# moonlight_application register map
Vendor: Nordic Semiconductor; Series: lumos; File version: 1
CPU: CM33 r0p4, little endian, MPU, FPU, 3 interrupt priority bits, 176 interrupts, 4 SAU regions
Registers are 32-bit, read-write, reset 0x0 unless marked. A register's access mark holds for its fields unless they carry their own. Offsets are from the block's base; [hi:lo] are bit positions; lines under a group give offsets from that group; {n}, {i} and the like mark numbered series; 'fields as' and 'values as' point back to an identical list.

## GLOBAL_REGULATORS_NS — Voltage regulators 0
Base 0x40120000; alternate view of GLOBAL_OSCILLATORS_NS
Same registers: GLOBAL_REGULATORS_S 0x50120000 (alternate view of GLOBAL_OSCILLATORS_S)
0x400 VREGM group — Medium Voltage Regulator
  0x00 ENABLE reset 0x1 — Unspecified
    [0] ENABLE — Enable the regulator
      0=Disabled (Disable the regulator); 1=Enabled (Enable the regulator)
  0x10 VOLT — Set output voltage
    [2:0] VOLT
      0=2V6 (2.6 V); 1=2V7 (2.7 V); 2=2V8 (2.8 V); 3=2V9 (2.9 V); 4=3V0 (3.0 V); 5=3V1 (3.1 V); 6=3V2 (3.2 V); 7=3V3 (3.3 V)
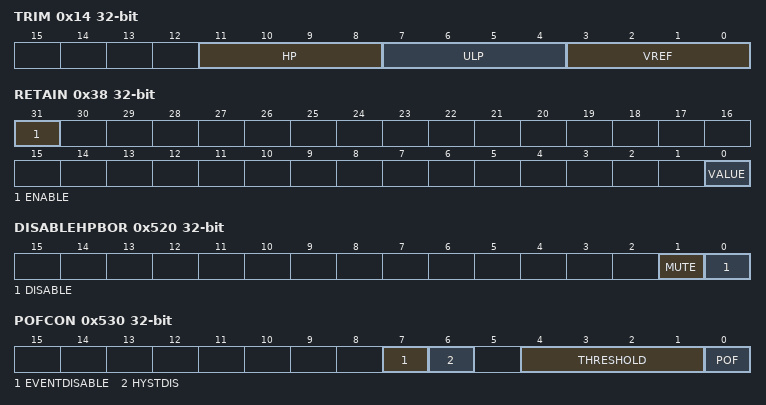
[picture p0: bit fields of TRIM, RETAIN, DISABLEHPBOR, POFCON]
  0x14 TRIM — Unspecified
    [11:8] HP — VOUT
    [7:4] ULP — VOUTCOMP TH ie Refresh Ripple
    [3:0] VREF — VFREF_MBIAS
  0x30 READY ro — Unspecified
    [0] READY — Regulator ready
  0x34 BPREADY ro — Unspecified
    [0] BPREADY — Bypass mode flag
  0x38 RETAIN — Override the retention control signal to the regulator for testing.
    [31] ENABLE — Override enable
    [0] VALUE — Override value
  0x3C DTBCFG — Unspecified
    [2:0] DTB0CFG — Using 3 bits of DTB0CFG allows to hook four internal signals to DTB. VOUTCMP is needed for test but others are free choice for debug.
      4=VOUTCOMP (Unspecified); 5=PWRUPFB (Unspecified); 6=PWRUPVREG (Unspecified); 7=BYPASS (Unspecified)
  0x40 TCFG — Unspecified
    [7:0] TCFG — TCFG test force configuration bus.
      0=PWRUPVOUTCMP (Unspecified); 2=PWRUPFB (Unspecified); 4=PWRUPVREG (Unspecified); 8=BYPASS (Unspecified); 16=FORCEULP (Unspecified); 32=FORCEBP (Unspecified); 64=DISABLEMBIAS (Unspecified); 128=RESETDIG (Unspecified)
0x500 SYSTEMOFF wo
  [0] SYSTEMOFF — Enable System OFF mode
    1=Enter (Enable System OFF mode)
0x520 DISABLEHPBOR wo — Enable or disable HPBOR
  [1] MUTE — Mute or unmute HPBOR
    0=Unmuted (Unmute HPBOR); 1=Muted (Mute HPBOR)
  [0] DISABLE — Enable or disable HPBOR
    0=Enabled (Enable HPBOR); 1=Disabled (Disable HPBOR)
0x524 BIASREQUEST — Request BIAS module
  [0] REQ
    0=Automatic (Bias is requested automatically by users); 1=Requested (Bias is always requested)
0x530 POFCON — Power-fail comparator configuration
  [7] EVENTDISABLE — Disable the POFWARN power-fail warning event
    0=Enabled (POFWARN event is generated); 1=Disabled (POFWARN event is not generated)
  [6] HYSTDIS — Bypass power-fail comparator hysteresis
    0=Normal (Hysteresis active); 1=NoHyst (Hysteresis disabled)
  [4:1] THRESHOLD — Power-fail comparator threshold setting
    4=V17 (Set threshold to 1.7 V); 5=V18 (Set threshold to 1.8 V); 6=V19 (Set threshold to 1.9 V); 7=V20 (Set threshold to 2.0 V); 8=V21 (Set threshold to 2.1 V); 9=V22 (Set threshold to 2.2 V); 10=V23 (Set threshold to 2.3 V); 11=V24 (Set threshold to 2.4 V); 12=V25 (Set threshold to 2.5 V); 13=V26 (Set threshold to 2.6 V); 14=V27 (Set threshold to 2.7 V); 15=V28 (Set threshold to 2.8 V)
  [0] POF — Enable or disable power-fail comparator
    0=Disabled; 1=Enabled
0x534 POFSTAT ro — Power-fail comparator status register
  [0] COMPARATOR — Power-fail comparator status
    0=Above (Voltage detected above VPOF threshold); 1=Below (Voltage detected below VPOF threshold)
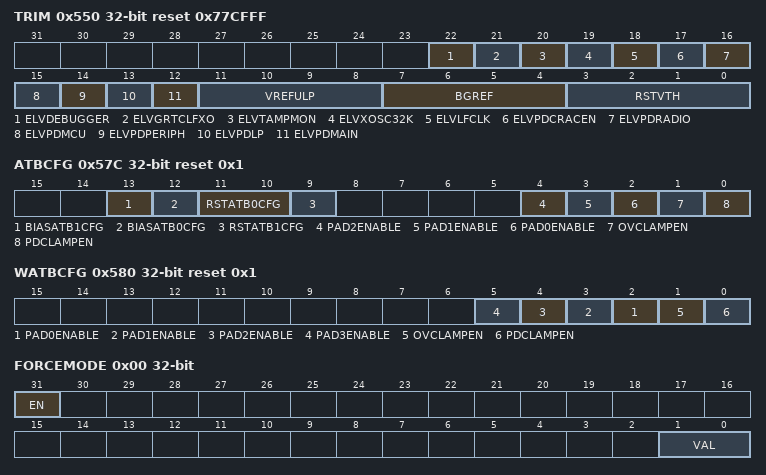
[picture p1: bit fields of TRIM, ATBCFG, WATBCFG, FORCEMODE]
0x550 TRIM reset 0x77CFFF — TRIM values
  [22] ELVDEBUGGER — Allow or prevent ELV mode when DEBUGGER is connected
    0=Allow ELV mode when DEBUGGER is connected; 1=Prevent ELV mode when DEBUGGER is connected
  [21] ELVGRTCLFXO — Allow or prevent ELV mode when GRTC is ON in LFXO source
    0=Allow ELV mode when GRTC is ON in LFXO source; 1=Prevent ELV mode when GRTC is ON in LFXO source
  [20] ELVTAMPMON — Allow or prevent ELV mode when TAMPMON is ON
    0=Allow ELV mode when TAMPMON is ON; 1=Prevent ELV mode when TAMPMON is ON
  [19] ELVXOSC32K — Allow or prevent ELV mode when XOSC32K is ON
    0=Allow ELV mode when XOSC32K is ON; 1=Prevent ELV mode when XOSC32K is ON
  [18] ELVLFCLK — Allow or prevent ELV mode when LFCLK is ON
    0=Allow ELV mode when LFCLK is ON; 1=Prevent ELV mode when LFCLK is ON
  [17] ELVPDCRACEN — Allow or prevent ELV mode when PD_CRACEN is ON
    0=Allow ELV mode when PD_CRACEN is ON; 1=Prevent ELV mode when PD_CRACEN is ON
  [16] ELVPDRADIO — Allow or prevent ELV mode when PD_RADIO is ON
    0=Allow ELV mode when PD_RADIO is ON; 1=Prevent ELV mode when PD_RADIO is ON
  [15] ELVPDMCU — Allow or prevent ELV mode when PD_PERIPH is ON
    0=Allow ELV mode when PD_PERIPH is ON; 1=Prevent ELV mode when PD_PERIPH is ON
  [14] ELVPDPERIPH — Allow or prevent ELV mode when PD_PERIPH is ON
    values as ELVPDMCU
  [13] ELVPDLP — Allow or prevent ELV mode when PD_LP is ON
    0=Allow ELV mode when PD_LP is ON; 1=Prevent ELV mode when PD_LP is ON
  [12] ELVPDMAIN — Allow or prevent ELV mode when PD_MAIN is ON
    0=Allow ELV mode when PD_MAIN is ON; 1=Prevent ELV mode when PD_MAIN is ON
  [11:8] VREFULP — Trim value of VREF_ULP
  [7:4] BGREF — Master bias bandgap trim
  [3:0] RSTVTH — Threshold trim, power-on reset
0x57C ATBCFG reset 0x1 — Analog test bus control
  [13] BIASATB1CFG — Connect or disconnect MBIAS to analog test bus
    0=Disconnect from analog test bus; 1=Connect IBPSR_8U current to ATB1
  [12] BIASATB0CFG — Connect or disconnect MBIAS to analog test bus
    0=Disconnect from analog test bus; 1=Connect VBG voltage to ATB0
  [11:10] RSTATB0CFG — Configure connection of RST to analog test bus
    0=Disconnect from analog test bus; 1=AVDD_DIV2 connected to ATB0; 2=VREF_ULP connected to ATB0; 3=VBG_RST connected to ATB0
  [9] RSTATB1CFG — Configure connection of RST to analog test bus
    0=Disconnect from analog test bus; 1=Connect (IBPP connected to ATB1)
  [4] PAD2ENABLE — Enable or disable ATB2 pad
    0=Disabled (Disable pad); 1=Enable pad
  [3] PAD1ENABLE — Enable or disable ATB1 pad
    0=Disabled (Disable pad); 1=Enable pad
  [2] PAD0ENABLE — Enable or disable ATB0 pad
    0=Disabled (Disable pad); 1=Enable pad
  [1] OVCLAMPEN — Enable or disable overvoltage clamp on ATB
    0=Disabled (Disable overvoltage clamp); 1=Enable overvoltage clamp
  [0] PDCLAMPEN — Enable or disable power-down clamp on ATB
    0=Disable power-down clamp; 1=Enable power-down clamp
0x580 WATBCFG reset 0x1 — WATB control
  [n+2] PAD{n}ENABLE (n=0..3) — Enable or disable WATB{n} pad
    0=Disabled (Disable pad); 1=Enable pad
  [1] OVCLAMPEN — Enable or disable overvoltage clamp on WATB
    values as ATBCFG.OVCLAMPEN
  [0] PDCLAMPEN — Enable or disable power-down clamp on WATB
    0=Disable power-down clamp; 1=Enable power-down clamp
0x600 VREGMAIN group — Main voltage regulator
  0x00 DCDCEN — Enable DC/DC converter for better power efficiency
    [0] VAL — Enable DC/DC converter
      0=Disable DC/DC converter and use LDO; 1=Enable DC/DC converter
  0x04 INDUCTORDET ro — VREGMAIN inductor detection
    [0] DETECTED
      0=InductorNotDetected (VREGMAIN inductor not detected); 1=InductorDetected (VREGMAIN inductor detected)
  0x08 STATUS ro — Voltage regulator status
    [5:0] MODE — Current voltage regulator mode
      8=Ext (External supply mode); 9=Ldo (Linear low drop output mode - a high power, low efficiency mode); 10=Pfm (Pulse frequency modulation mode - a low power, high efficiency mode); 12=Pwm (Pulse width modulation mode - a high power, high efficiency, and clean power (low noise) mode); 1=Reset mode; 41=ExtLdo (Transition state between EXT to LDO); 11=PfmLdo (Transition state between PFM to LDO); 13=LdoPwm (Transition state between LDO and PWM); 14=PfmPwm (Transition state between PFM to PWM); 46=PwmPfm (Transition state between PWM to PFM); 28=PwmIcmp (Transition state between PWM to PWM_PFM, where the FSM waits for the PWM ICMP)
  0x0C PFMICMPRUNNING ro — Current PFM ICMP status
    [0] TIMERRUNNING
      0=NotRunning (PFM ICMP timer is not running); 1=Running (PFM ICMP timer is running)
  0x10 PFMICMPFLAG — PFM ICMP has been triggered (write one to clear it)
    [0] PFMICMPFLAG
      0=NotTriggered (PFM ICMP has not been triggered); 1=Triggered (PFM ICMP has been triggered)
  0x14 BUCKLSCOUNT ro — Read counter output controlling low-side current threshold for PFM mode
    [4:0] BUCKLSCOUNT
  0x18 CONFIG group — Configure the MMI behavior
    0x00 FORCEMODE — Force voltage regulator into a certain mode
      [31] EN — Enable force mode for the regulator
        0=Disabled (Force mode is disabled); 1=Enabled (Force mode is enabled)
      [1:0] VAL — Current voltage regulator mode
        0=Ext (Force to external supply mode); 1=Ldo (Force to LDO mode); 2=Pfm (Force to PFM mode); 3=Pwm (Force to PWM mode)
    0x04 DEBUGCONTROL — Analog module debug control signals
      [7:0] VAL
        0=Bit0 (Enable resistive feedback for DC/DC converter (PFM mode)); 1=Bit1 (Turn off P_DCC_LP (PWM mode)); 2=Bit2 (Prevent comparator from turning off high side driver (PFM mode)); 3=Bit3 (Force BUCK_ICMP_0V9 to 0 (PFM mode)); 4=Bit4 (Force low side driver on); 5=Bit5 (Force high side driver on)
    0x08 VREGENLOAD — Enable test load for P_LR0V9 pad
      [0] VAL
        0=NormalOperation (No load); 1=TestLoad (88 Ohm test load, about 10mA load current at 0.9V)
    0x0C BUCKSETLSCOUNTER — Force the counter in the zero-cross detector to the set value for PFM mode
      [5:0] BUCKSETLSCOUNTER
    0x10 REQUESTEXTERNAL — Request external mode, and switch OFF the regulator
      [0] VAL — Request external mode for the regulator
        0=Disabled (External mode is not requested); 1=Enabled (External mode is requested)
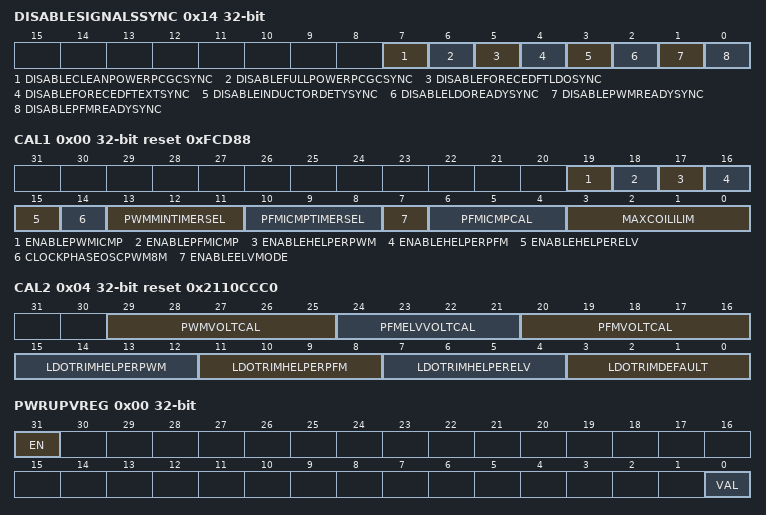
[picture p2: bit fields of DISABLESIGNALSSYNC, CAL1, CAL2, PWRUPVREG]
    0x14 DISABLESIGNALSSYNC — Disable Signals synchronization
      [all] fields
        0=Enable (Synchronization is enabled); 1=Disable (Synchronization is disabled)
      [7] DISABLECLEANPOWERPCGCSYNC — Disable cleanPowerPcgc signal synchronization
      [6] DISABLEFULLPOWERPCGCSYNC — Disable fullPowerPcgc signal synchronization
      [5] DISABLEFORECEDFTLDOSYNC — Disable forceDftLdo signal synchronization
      [4] DISABLEFORECEDFTEXTSYNC — Disable forceDftExt signal synchronization
      [3] DISABLEINDUCTORDETYSYNC — Disable inductorDetect signal synchronization
      [2] DISABLELDOREADYSYNC — Disable ldoReady signal synchronization
      [1] DISABLEPWMREADYSYNC — Disable pwmReady signal synchronization
      [0] DISABLEPFMREADYSYNC — Disable pfmReady signal synchronization
    0x18 ATB0CFG — Analog testbus 0 configuration
      [3:0] ATB0CFG
        0=HiZ (Allow other IPs to use ATB0); 1=InvertedBuckComparator (Inverting input of buck comparator); 2=InvertedBuckErrorAmplifier (Inverting input of buck error amplifier); 3=BuckInternalRegerence (Buck Internal bandgap reference); 4=VDD analog voltage; 5=VDD digital voltage
    0x1C ATB1CFG — Analog testbus 1 configuration
      [3:0] ATB1CFG
        0=HiZ (Allow other IPs to use ATB1); 1=BuckComparator (Non-inverting input of buck comparator); 2=BuckErrorAmplifier (Output of buck error amplifier); {v}=VSS{v-3} (VSS analog voltage) (v=4..7)
    0x20 DTB0CFG — Digital testbus 0 configuration
      [2:0] DTB0CFG
        0=Dtb0Low (Allow other IPs to use DTB0); 1=BuckLsIlim (TODO: Update abstract); 2=CmpBuf (TODO: Update abstract); 3=AfsmS0 (TODO: Update abstract)
    0x24 DTB1CFG — Digital testbus 1 configuration
      [2:0] DTB1CFG
        0=Dtb1Low (Allow other IPs to use DTB1); 1=BuckHsIlim (TODO: Update abstract); 2=BuckPfmIcmp (TODO: Update abstract); 3=AfsmS1 (TODO: Update abstract)
  0x40 CALIBRATION group — Calibration values written from FICR
    0x00 CAL1 reset 0xFCD88 — Unspecified
      [19] ENABLEPWMICMP — Enable PWM ICMP (to auto detect no high load current is present)
      [18] ENABLEPFMICMP — Enable PFM ICMP (to auto detect high load)
      [17] ENABLEHELPERPWM — Enable helper mode in PWM mode (LDO will be powered ON)
      [16] ENABLEHELPERPFM — Enable helper mode in PFM mode (LDO will be powered ON)
      [15] ENABLEHELPERELV — Enable fast exit from ELV (helper mode in ELV, LDO will be powered ON)
      [14] CLOCKPHASEOSCPWM8M — Configure the generated DCDC clock phase (for PWM mode) with respect to the orignal system clock, 0 in phase and 1 is out of phase
      [13:11] PWMMINTIMERSEL — Configure the minimum time to stay in PWM mode after a PWM mode request. The timer has a minimum value of 32us and maximum value of 256us (value = ((32*(n + 1) - 1))us), with linear increments of 32us (32us, 64us, 96us, etc..) with 3 bits to select the timer value
      [10:8] PFMICMPTIMERSEL — Configure the time to stay in PWM mode after a PFM ICMP request. The timer has a minimum value of 32us and maximum value of 4ms (value = ((32*(2^n) - 1))us), with exponential increments (32us, 64us, 128us, etc..) with 3 bits to select the timer value
      [7] ENABLEELVMODE — Enable ELV mode (Extreme Low Voltage) to be automatically switched to in PFM mode if there is no power requests
      [6:4] PFMICMPCAL — Calibration of PFM mode overcurrent comparator through duty cycle control (2's complement)
      [3:0] MAXCOILILIM — Set coil current limit to avoid core saturation
    0x04 CAL2 reset 0x2110CCC0 — Unspecified
      [29:25] PWMVOLTCAL — Calibration of BUCK_LP_PWM output voltage
      [24:21] PFMELVVOLTCAL — Calibration of ELV output voltage
      [20:16] PFMVOLTCAL — Calibration of BUCK_LP_PFM output voltage
      [15:12] LDOTRIMHELPERPWM — Calibration of LDO reference voltage for PWM helper mode operation, 2nd complement
      [11:8] LDOTRIMHELPERPFM — Calibration of LDO reference voltage for PFM helper mode operation, 2nd complement
      [7:4] LDOTRIMHELPERELV — Calibration of LDO reference voltage for ELV helper mode operation, 2nd complement
      [3:0] LDOTRIMDEFAULT — Calibration of LDO reference voltage for normal operation, 2nd complement
  0x48 OVERRIDE group — Override analog IP signals
    0x00 PWRUPVREG — Override the PWRUP signal for LDO (Vreg) to the analog module
      [31] EN — Enable the override
        0=Disabled (Override is disabled); 1=Enabled (Override is enabled)
      [0] VAL — Override value
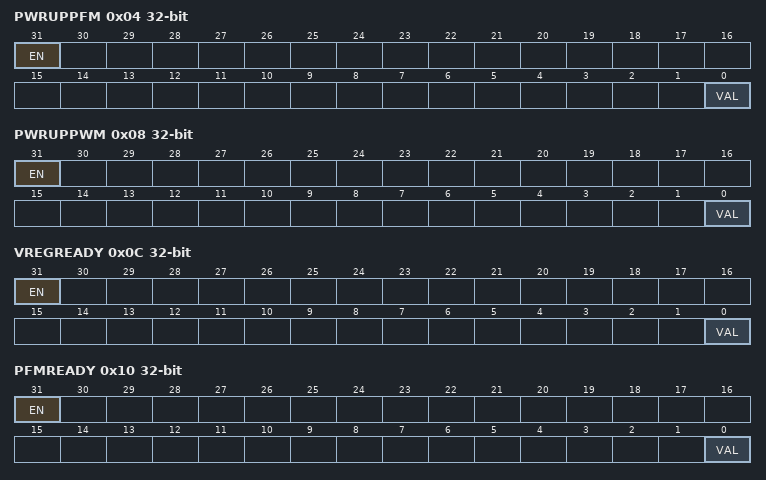
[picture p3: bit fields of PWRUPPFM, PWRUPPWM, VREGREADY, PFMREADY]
    0x04 PWRUPPFM — Override the PWRUP signal for PFM to the analog module
      fields as VREGMAIN.OVERRIDE.PWRUPVREG
    0x08 PWRUPPWM — Override the PWRUP signal for PWM to the analog module
      fields as VREGMAIN.OVERRIDE.PWRUPVREG
    0x0C VREGREADY — Override the Ready signal of LDO (Vreg) from the analog module
      fields as VREGMAIN.OVERRIDE.PWRUPVREG
    0x10 PFMREADY — Override the Ready signal of PFM from the analog module
      fields as VREGMAIN.OVERRIDE.PWRUPVREG
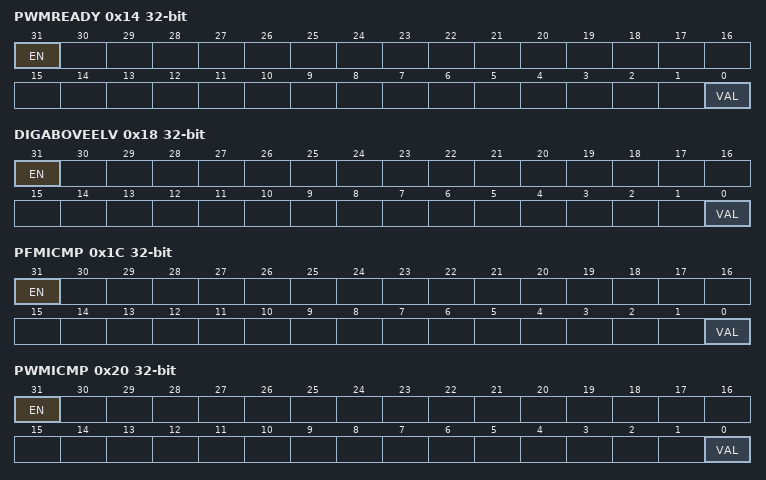
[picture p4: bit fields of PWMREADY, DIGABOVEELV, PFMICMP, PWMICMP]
    0x14 PWMREADY — Override the Ready signal of PWM from the analog module
      fields as VREGMAIN.OVERRIDE.PWRUPVREG
    0x18 DIGABOVEELV — Override the pwrAboveElv signal from the analog module
      [31] EN — Enable the override
        values as VREGMAIN.OVERRIDE.PWRUPVREG.EN
      [0] VAL — Override value for the signal
    0x1C PFMICMP — Override the PfmIcmp signal from the analog module
      [31] EN — Enable the override
        values as VREGMAIN.OVERRIDE.PWRUPVREG.EN
      [0] VAL — Current value of the signal
    0x20 PWMICMP — Override the PwmIcmp signal from the analog module
      fields as VREGMAIN.OVERRIDE.PFMICMP
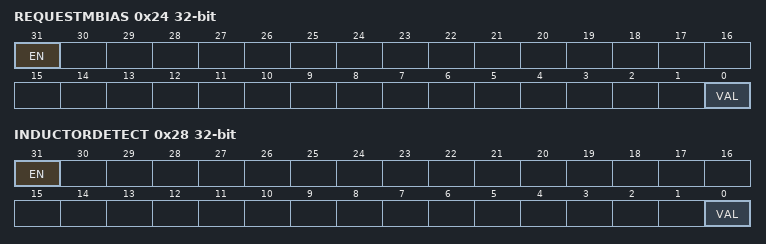
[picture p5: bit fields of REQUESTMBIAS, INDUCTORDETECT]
    0x24 REQUESTMBIAS — Override the requestMbias_a signal from the MMI
      [31] EN — Enable the override
        values as VREGMAIN.OVERRIDE.PWRUPVREG.EN
      [0] VAL — Override value of the signal
    0x28 INDUCTORDETECT — Override the Buck Inductor Detected signal from the analog module
      fields as VREGMAIN.OVERRIDE.PFMICMP
